# STM32G534 register map
File version: 2.0.0
CPU: CM33 r0p4, little endian, MPU, FPU, 4 interrupt priority bits
Registers are 32-bit, read-write, reset 0x0 unless marked. A register's access mark holds for its fields unless they carry their own. Offsets are from the block's base; [hi:lo] are bit positions; {n}, {i} and the like mark numbered series.

## GTZC1_TZIC — GTZC1_TZIC register block
Base 0x40032800
Same registers: GTZC1_TZIC_S 0x50032800
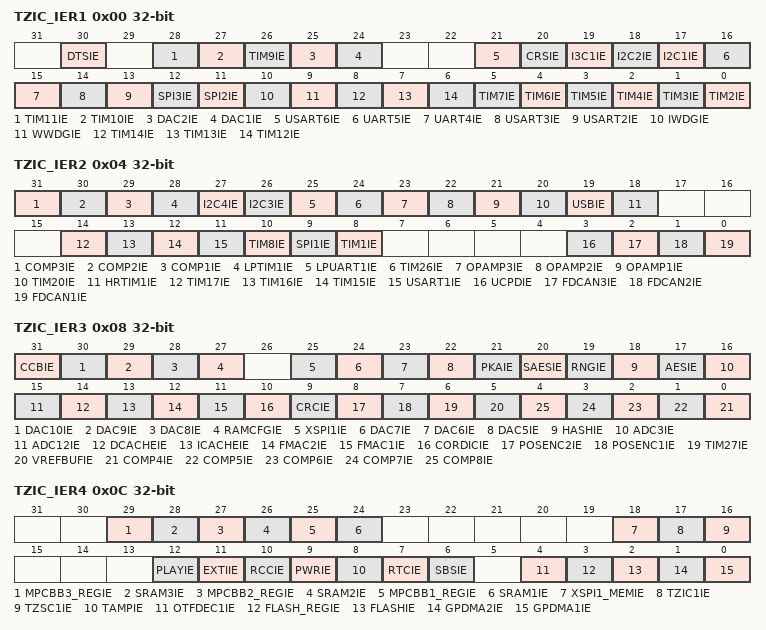
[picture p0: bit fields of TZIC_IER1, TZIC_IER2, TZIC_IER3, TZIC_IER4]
0x00 TZIC_IER1 — TZIC interrupt enable register 1
  [all] fields
    0=interrupt disabled; 1=interrupt enabled
  [30] DTSIE — illegal access interrupt enable for DTS
  [28] TIM11IE — illegal access interrupt enable for TIM11
  [27] TIM10IE — illegal access interrupt enable for TIM10
  [26] TIM9IE — illegal access interrupt enable for TIM9
  [25] DAC2IE — illegal access interrupt enable for DAC2
  [24] DAC1IE — illegal access interrupt enable for DAC1
  [21] USART6IE — illegal access interrupt enable for USART6
  [20] CRSIE — illegal access interrupt enable for CRS
  [19] I3C1IE — illegal access interrupt enable for I3C1
  [18] I2C2IE — illegal access interrupt enable for I2C2
  [17] I2C1IE — illegal access interrupt enable for I2C1
  [16] UART5IE — illegal access interrupt enable for UART5
  [15] UART4IE — illegal access interrupt enable for UART4
  [14] USART3IE — illegal access interrupt enable for USART3
  [13] USART2IE — illegal access interrupt enable for USART2
  [12] SPI3IE — illegal access interrupt enable for SPI3
  [11] SPI2IE — illegal access interrupt enable for SPI2
  [10] IWDGIE — illegal access interrupt enable for IWDG
  [9] WWDGIE — illegal access interrupt enable for WWDG
  [8] TIM14IE — illegal access interrupt enable for TIM14
  [7] TIM13IE — illegal access interrupt enable for TIM13
  [6] TIM12IE — illegal access interrupt enable for TIM12
  [n-2] TIM{n}IE (n=2..7) — illegal access interrupt enable for TIM{n}
0x04 TZIC_IER2 — TZIC interrupt enable register 2
  [all] fields
    0=interrupt disabled; 1=interrupt enabled
  [31] COMP3IE — illegal access interrupt enable for COMP3
  [30] COMP2IE — illegal access interrupt enable for COMP2
  [29] COMP1IE — illegal access interrupt enable for COMP1
  [28] LPTIM1IE — illegal access interrupt enable for LPTIM1
  [27] I2C4IE — illegal access interrupt enable for I2C4
  [26] I2C3IE — illegal access interrupt enable for I2C3
  [25] LPUART1IE — illegal access interrupt enable for LPUART1
  [24] TIM26IE — illegal access interrupt enable for TIM26
  [23] OPAMP3IE — illegal access interrupt enable for OPAMP3
  [22] OPAMP2IE — illegal access interrupt enable for OPAMP2
  [21] OPAMP1IE — illegal access interrupt enable for OPAMP1
  [20] TIM20IE — illegal access interrupt enable for TIM20
  [19] USBIE — illegal access interrupt enable for USB
  [18] HRTIM1IE — illegal access interrupt enable for HRTIM1
  [14] TIM17IE — illegal access interrupt enable for TIM17
  [13] TIM16IE — illegal access interrupt enable for TIM16
  [12] TIM15IE — illegal access interrupt enable for TIM15
  [11] USART1IE — illegal access interrupt enable for USART1
  [10] TIM8IE — illegal access interrupt enable for TIM8
  [9] SPI1IE — illegal access interrupt enable for SPI1
  [8] TIM1IE — illegal access interrupt enable for TIM1
  [3] UCPDIE — illegal access interrupt enable for UCPD
  [2] FDCAN3IE — illegal access interrupt enable for FDCAN3
  [1] FDCAN2IE — illegal access interrupt enable for FDCAN2
  [0] FDCAN1IE — illegal access interrupt enable for FDCAN1
0x08 TZIC_IER3 — TZIC interrupt enable register 3
  [31] CCBIE — illegal access interrupt enable for CCB
    0=interrupt disabled; 1=interrupt enabled
  [30] DAC10IE — illegal access interrupt enable for DAC10
    0=interrupt disabled; 1=interrupt enabled
  [29] DAC9IE — illegal access interrupt enable for DAC9
    0=interrupt disabled; 1=interrupt enabled
  [28] DAC8IE — illegal access interrupt enable for DAC8
    0=interrupt disabled; 1=interrupt enabled
  [27] RAMCFGIE — illegal access interrupt enable for RAMCFG
    0=interrupt disabled; 1=interrupt enabled
  [25] XSPI1IE — illegal access interrupt enable for XSPI1
    0=interrupt disabled; 1=interrupt enabled
  [24] DAC7IE — illegal access interrupt enable for DAC7
    0=interrupt disabled; 1=interrupt enabled
  [23] DAC6IE — illegal access interrupt enable for DAC6
    0=interrupt disabled; 1=interrupt enabled
  [22] DAC5IE — illegal access interrupt enable for DAC5
    0=interrupt disabled; 1=interrupt enabled
  [21] PKAIE — illegal access interrupt enable for PKA
    0=interrupt disabled; 1=interrupt enabled
  [20] SAESIE — illegal access interrupt enable for SAES
    0=interrupt disabled; 1=interrupt enabled
  [19] RNGIE — illegal access interrupt enable for RNG
    0=interrupt disabled; 1=interrupt enabled
  [18] HASHIE — illegal access interrupt enable for HASH
    0=interrupt disabled; 1=interrupt enabled
  [17] AESIE — illegal access interrupt enable for AES
    0=interrupt disabled; 1=interrupt enabled
  [16] ADC3IE — illegal access interrupt enable for ADC3
    0=interrupt disabled; 1=interrupt enabled
  [15] ADC12IE — illegal access interrupt enable for ADC1 and ADC2
    0=interrupt disabled; 1=interrupt enabled
  [14] DCACHEIE — illegal access interrupt enable for DCACHE
    0=interrupt disabled; 1=interrupt enabled
  [13] ICACHEIE — illegal access interrupt enable for ICACHE
    0=interrupt disabled; 1=interrupt enabled
  [12] FMAC2IE — illegal access interrupt enable for register of FMAC2
    0=interrupt disabled; 1=interrupt enabled
  [11] FMAC1IE — illegal access interrupt enable for register of FMAC1
    0=interrupt disabled; 1=interrupt enabled
  [10] CORDICIE — illegal access interrupt enable for CORDIC
    0=interrupt disabled; 1=interrupt enabled
  [9] CRCIE — illegal access interrupt enable for CRC
    0=interrupt disabled; 1=interrupt enabledh
  [8] POSENC2IE — illegal access interrupt enable for POSENC2
    0=interrupt disabled; 1=interrupt enabled
  [7] POSENC1IE — illegal access interrupt enable for POSENC1
    0=interrupt disabled; 1=interrupt enabled
  [6] TIM27IE — illegal access interrupt enable for TIM27
    0=interrupt disabled; 1=interrupt enabled
  [5] VREFBUFIE — illegal access interrupt enable for VREFBUF
    0=interrupt disabled; 1=interrupt enabled
  [n-4] COMP{n}IE (n=4..8) — illegal access interrupt enable for COMP{n}
    0=interrupt disabled; 1=interrupt enabled
0x0C TZIC_IER4 — TZIC interrupt enable register 4
  [all] fields
    0=interrupt disabled; 1=interrupt enabled
  [29] MPCBB3_REGIE — illegal access interrupt enable for MPCBB3 registers
  [28] SRAM3IE — illegal access interrupt enable for SRAM3
  [27] MPCBB2_REGIE — illegal access interrupt enable for MPCBB2 registers
  [26] SRAM2IE — illegal access interrupt enable for SRAM2
  [25] MPCBB1_REGIE — illegal access interrupt enable for MPCBB1 registers
  [24] SRAM1IE — illegal access interrupt enable for SRAM1
  [18] XSPI1_MEMIE — illegal access interrupt enable for MPCWM1 (XSPI1) memory bank
  [17] TZIC1IE — illegal access interrupt enable for GTZC1 TZIC registers
  [16] TZSC1IE — illegal access interrupt enable for GTZC1 TZSC registers
  [12] PLAYIE — illegal access interrupt enable for PLAY
  [11] EXTIIE — illegal access interrupt enable for EXTI
  [10] RCCIE — illegal access interrupt enable for RCC
  [9] PWRIE — illegal access interrupt enable for PWR
  [8] TAMPIE — illegal access interrupt enable for TAMP
  [7] RTCIE — illegal access interrupt enable for RTC
  [6] SBSIE — illegal access interrupt enable for SBS
  [4] OTFDEC1IE — illegal access interrupt enable for OTFDEC1
  [3] FLASH_REGIE — illegal access interrupt enable for FLASH memory
  [2] FLASHIE — illegal access interrupt enable for FLASH registers
  [1] GPDMA2IE — illegal access interrupt enable for GPDMA2
  [0] GPDMA1IE — illegal access interrupt enable for GPDMA1
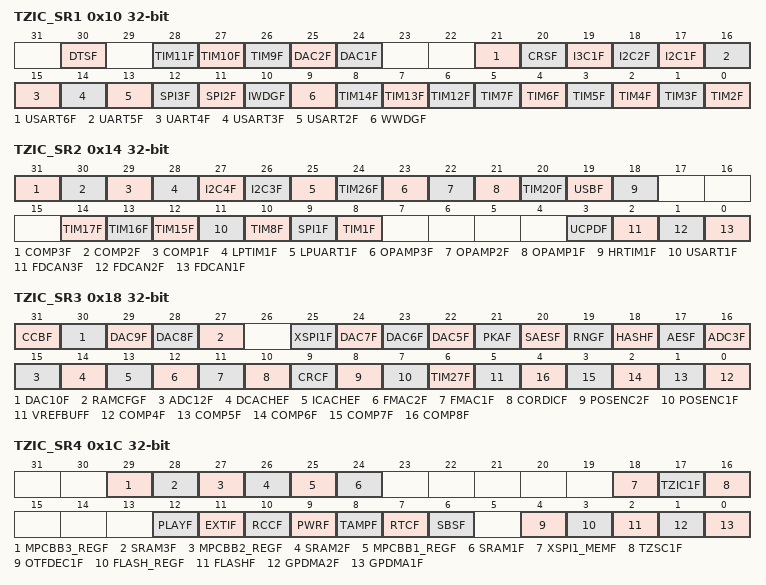
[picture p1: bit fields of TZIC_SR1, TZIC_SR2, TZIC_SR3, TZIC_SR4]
0x10 TZIC_SR1 ro — TZIC status register 1
  [all] fields
    0=no illegal access event; 1=illegal access event
  [30] DTSF — illegal access flag for DTS
  [28] TIM11F — illegal access flag for TIM11
  [27] TIM10F — illegal access flag for TIM10
  [26] TIM9F — illegal access flag for TIM9
  [25] DAC2F — illegal access flag for DAC2
  [24] DAC1F — illegal access flag for DAC1
  [21] USART6F — illegal access flag for USART6
  [20] CRSF — illegal access flag for CRS
  [19] I3C1F — illegal access flag for I3C1
  [18] I2C2F — illegal access flag for I2C2
  [17] I2C1F — illegal access flag for I2C1
  [16] UART5F — illegal access flag for UART5
  [15] UART4F — illegal access flag for UART4
  [14] USART3F — illegal access flag for USART3
  [13] USART2F — illegal access flag for USART2
  [12] SPI3F — illegal access flag for SPI3
  [11] SPI2F — illegal access flag for SPI2
  [10] IWDGF — illegal access flag for IWDG
  [9] WWDGF — illegal access flag for WWDG
  [8] TIM14F — illegal access flag for TIM14
  [7] TIM13F — illegal access flag for TIM13
  [6] TIM12F — illegal access flag for TIM12
  [n-2] TIM{n}F (n=2..7) — illegal access flag for TIM{n}
0x14 TZIC_SR2 ro — TZIC status register 2
  [all] fields
    0=no illegal access event; 1=illegal access event
  [31] COMP3F — illegal access flag for COMP3
  [30] COMP2F — illegal access flag for COMP2
  [29] COMP1F — illegal access flag for COMP1
  [28] LPTIM1F — illegal access flag for LPTIM1
  [27] I2C4F — illegal access flag for I2C4
  [26] I2C3F — illegal access flag for I2C3
  [25] LPUART1F — illegal access flag for LPUART1
  [24] TIM26F — illegal access flag for TIM26
  [23] OPAMP3F — illegal access flag for OPAMP3
  [22] OPAMP2F — illegal access flag for OPAMP2
  [21] OPAMP1F — illegal access flag for OPAMP1
  [20] TIM20F — illegal access flag for TIM20
  [19] USBF — illegal access flag for USB
  [18] HRTIM1F — illegal access flag for HRTIM1
  [14] TIM17F — illegal access flag for TIM17
  [13] TIM16F — illegal access flag for TIM16
  [12] TIM15F — illegal access flag for TIM15
  [11] USART1F — illegal access flag for USART1
  [10] TIM8F — illegal access flag for TIM8
  [9] SPI1F — illegal access flag for SPI1
  [8] TIM1F — illegal access flag for TIM1
  [3] UCPDF — illegal access flag for UCPD
  [2] FDCAN3F — illegal access flag for FDCAN3
  [1] FDCAN2F — illegal access flag for FDCAN2
  [0] FDCAN1F — illegal access flag for FDCAN1
0x18 TZIC_SR3 ro — TZIC status register 3
  [all] fields
    0=no illegal access event; 1=illegal access event
  [31] CCBF — illegal access flag for CCB
  [30] DAC10F — illegal access flag for DAC10
  [29] DAC9F — illegal access flag for DAC9
  [28] DAC8F — illegal access flag for DAC8
  [27] RAMCFGF — illegal access flag for RAMCFG
  [25] XSPI1F — illegal access flag for XSPI1
  [24] DAC7F — illegal access flag for DAC7
  [23] DAC6F — illegal access flag for DAC6
  [22] DAC5F — illegal access flag for DAC5
  [21] PKAF — illegal access flag for PKA
  [20] SAESF — illegal access flag for SAES
  [19] RNGF — illegal access flag for RNG
  [18] HASHF — illegal access flag for HASH
  [17] AESF — illegal access flag for AES
  [16] ADC3F — illegal access flag for ADC3
  [15] ADC12F — illegal access flag for ADC1 and ADC2
  [14] DCACHEF — illegal access flag for DCACHE
  [13] ICACHEF — illegal access flag for ICACHE
  [12] FMAC2F — illegal access flag for register for FMAC2
  [11] FMAC1F — illegal access flag for register for FMAC1
  [10] CORDICF — illegal access flag for CORDIC
  [9] CRCF — illegal access flag for CRC
  [8] POSENC2F — illegal access flag for POSENC2
  [7] POSENC1F — illegal access flag for POSENC1
  [6] TIM27F — illegal access flag for TIM27
  [5] VREFBUFF — illegal access flag for VREFBUF
  [n-4] COMP{n}F (n=4..8) — illegal access flag for COMP{n}
0x1C TZIC_SR4 ro — TZIC status register 4
  [all] fields
    0=no illegal access event; 1=illegal access event
  [29] MPCBB3_REGF — illegal access flag for MPCBB3 registers
  [28] SRAM3F — illegal access flag for SRAM3
  [27] MPCBB2_REGF — illegal access flag for MPCBB2 registers
  [26] SRAM2F — illegal access flag for SRAM2
  [25] MPCBB1_REGF — illegal access flag for MPCBB1 registers
  [24] SRAM1F — illegal access flag for SRAM1
  [18] XSPI1_MEMF — illegal access flag for MPCWM1 (XSPI1) memory bank
  [17] TZIC1F — illegal access flag for GTZC1 TZIC registers
  [16] TZSC1F — illegal access flag for GTZC1 TZSC registers
  [12] PLAYF — illegal access flag for PLAY
  [11] EXTIF — illegal access flag for EXTI
  [10] RCCF — illegal access flag for RCC
  [9] PWRF — illegal access flag for PWR
  [8] TAMPF — illegal access flag for TAMP
  [7] RTCF — illegal access flag for RTC
  [6] SBSF — illegal access flag for SBS
  [4] OTFDEC1F — illegal access flag for OTFDEC1
  [3] FLASH_REGF — illegal access flag for FLASH registers
  [2] FLASHF — illegal access flag for FLASH memory
  [1] GPDMA2F — illegal access flag for GPDMA2
  [0] GPDMA1F — illegal access flag for GPDMA1
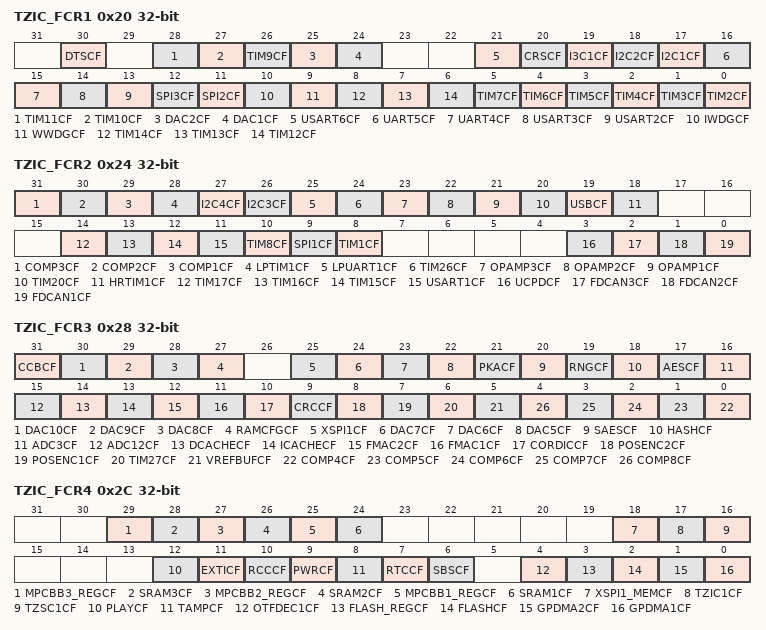
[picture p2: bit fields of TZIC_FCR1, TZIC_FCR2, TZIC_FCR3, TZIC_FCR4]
0x20 TZIC_FCR1 wo — TZIC flag clear register 1
  [all] fields
    0=no action; 1=status flag cleared
  [30] DTSCF — clear the illegal access flag for DTS
  [28] TIM11CF — clear the illegal access flag for TIM11
  [27] TIM10CF — clear the illegal access flag for TIM10
  [26] TIM9CF — clear the illegal access flag for TIM9
  [25] DAC2CF — clear the illegal access flag for DAC2
  [24] DAC1CF — clear the illegal access flag for DAC1
  [21] USART6CF — clear the illegal access flag for USART6
  [20] CRSCF — clear the illegal access flag for CRS
  [19] I3C1CF — clear the illegal access flag for I3C1
  [18] I2C2CF — clear the illegal access flag for I2C2
  [17] I2C1CF — clear the illegal access flag for I2C1
  [16] UART5CF — clear the illegal access flag for UART5
  [15] UART4CF — clear the illegal access flag for UART4
  [14] USART3CF — clear the illegal access flag for USART3
  [13] USART2CF — clear the illegal access flag for USART2
  [12] SPI3CF — clear the illegal access flag for SPI3
  [11] SPI2CF — clear the illegal access flag for SPI2
  [10] IWDGCF — clear the illegal access flag for IWDG
  [9] WWDGCF — clear the illegal access flag for WWDG
  [8] TIM14CF — clear the illegal access flag for TIM14
  [7] TIM13CF — clear the illegal access flag for TIM13
  [6] TIM12CF — clear the illegal access flag for TIM12
  [n-2] TIM{n}CF (n=2..7) — clear the illegal access flag for TIM{n}
0x24 TZIC_FCR2 wo — TZIC flag clear register 2
  [all] fields
    0=no action; 1=status flag cleared
  [31] COMP3CF — clear the illegal access flag for COMP3
  [30] COMP2CF — clear the illegal access flag for COMP2
  [29] COMP1CF — clear the illegal access flag for COMP1
  [28] LPTIM1CF — clear the illegal access flag for LPTIM1
  [27] I2C4CF — clear the illegal access flag for I2C4
  [26] I2C3CF — clear the illegal access flag for I2C3
  [25] LPUART1CF — clear the illegal access flag for LPUART1
  [24] TIM26CF — clear the illegal access flag for TIM26
  [23] OPAMP3CF — clear the illegal access flag for OPAMP3
  [22] OPAMP2CF — clear the illegal access flag for OPAMP2
  [21] OPAMP1CF — clear the illegal access flag for OPAMP1
  [20] TIM20CF — clear the illegal access flag for TIM20
  [19] USBCF — clear the illegal access flag for USB
  [18] HRTIM1CF — clear the illegal access flag for HRTIM1
  [14] TIM17CF — clear the illegal access flag for TIM17
  [13] TIM16CF — clear the illegal access flag for TIM16
  [12] TIM15CF — clear the illegal access flag for TIM15
  [11] USART1CF — clear the illegal access flag for USART1
  [10] TIM8CF — clear the illegal access flag for TIM8
  [9] SPI1CF — clear the illegal access flag for SPI1
  [8] TIM1CF — clear the illegal access flag for TIM1
  [3] UCPDCF — clear the illegal access flag for UCPD
  [2] FDCAN3CF — clear the illegal access flag for FDCAN3
  [1] FDCAN2CF — clear the illegal access flag for FDCAN2
  [0] FDCAN1CF — clear the illegal access flag for FDCAN1
0x28 TZIC_FCR3 wo — TZIC flag clear register 3
  [all] fields
    0=no action; 1=status flag cleared
  [31] CCBCF — clear the illegal access flag for CCB
  [30] DAC10CF — clear the illegal access flag for DAC10
  [29] DAC9CF — clear the illegal access flag for DAC9
  [28] DAC8CF — clear the illegal access flag for DAC8
  [27] RAMCFGCF — clear the illegal access flag for RAMCFG
  [25] XSPI1CF — clear the illegal access flag for XSPI1
  [24] DAC7CF — clear the illegal access flag for DAC7
  [23] DAC6CF — clear the illegal access flag for DAC6
  [22] DAC5CF — clear the illegal access flag for DAC5
  [21] PKACF — clear the illegal access flag for PKA
  [20] SAESCF — clear the illegal access flag for SAES
  [19] RNGCF — clear the illegal access flag for RNG
  [18] HASHCF — clear the illegal access flag for HASH
  [17] AESCF — clear the illegal access flag for AES
  [16] ADC3CF — clear the illegal access flag for ADC3
  [15] ADC12CF — clear the illegal access flag for ADC1 and ADC2
  [14] DCACHECF — clear the illegal access flag for DCACHE
  [13] ICACHECF — clear the illegal access flag for ICACHE
  [12] FMAC2CF — clear the illegal access flag for register of FMAC2
  [11] FMAC1CF — clear the illegal access flag for register of FMAC1
  [10] CORDICCF — clear the illegal access flag for CORDIC
  [9] CRCCF — clear the illegal access flag for CRC
  [8] POSENC2CF — clear the illegal access flag for POSENC2
  [7] POSENC1CF — clear the illegal access flag for POSENC1
  [6] TIM27CF — clear the illegal access flag for TIM27
  [5] VREFBUFCF — clear the illegal access flag for VREFBUF
  [n-4] COMP{n}CF (n=4..8) — clear the illegal access flag for COMP{n}
0x2C TZIC_FCR4 wo — TZIC flag clear register 4
  [all] fields
    0=no action; 1=status flag cleared
  [29] MPCBB3_REGCF — clear the illegal access flag for MPCBB3 registers
  [28] SRAM3CF — clear the illegal access flag for SRAM3
  [27] MPCBB2_REGCF — clear the illegal access flag for MPCBB2 registers
  [26] SRAM2CF — clear the illegal access flag for SRAM2
  [25] MPCBB1_REGCF — clear the illegal access flag for MPCBB1 registers
  [24] SRAM1CF — clear the illegal access flag for SRAM1
  [18] XSPI1_MEMCF — clear the illegal access flag for MPCWM1 (XSPI1) memory bank
  [17] TZIC1CF — clear the illegal access flag for GTZC1 TZIC registers
  [16] TZSC1CF — clear the illegal access flag for GTZC1 TZSC registers
  [12] PLAYCF — clear the illegal access flag for PLAY
  [11] EXTICF — clear the illegal access flag for EXTI
  [10] RCCCF — clear the illegal access flag for RCC
  [9] PWRCF — clear the illegal access flag for PWR
  [8] TAMPCF — clear the illegal access flag for TAMP
  [7] RTCCF — clear the illegal access flag for RTC
  [6] SBSCF — clear the illegal access flag for SBS
  [4] OTFDEC1CF — clear the illegal access flag for OTFDEC1
  [3] FLASH_REGCF — clear the illegal access flag for FLASH memory
  [2] FLASHCF — clear the illegal access flag for FLASH registers
  [1] GPDMA2CF — clear the illegal access flag for GPDMA2
  [0] GPDMA1CF — clear the illegal access flag for GPDMA1
